VERSION ""

NS_ :

BS_:

BU_: MASTER BRIDGE MOTOR SENSOR GPS

BO_ 103 BRIDGE_NODE: 1 BRIDGE
 SG_ BRIDGE_START : 0|1@1+ (1,0) [0|1] "" MASTER

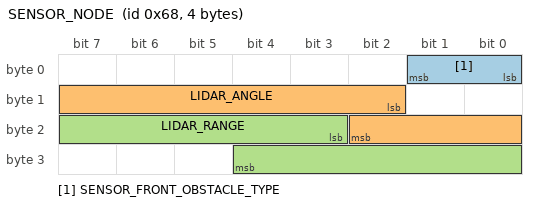
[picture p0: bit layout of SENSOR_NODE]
BO_ 104 SENSOR_NODE: 4 SENSOR
 SG_ SENSOR_FRONT_OBSTACLE_TYPE : 0|2@1+ (1,0) [0|0] "" MASTER
 SG_ LIDAR_ANGLE : 10|9@1+ (1,0) [0|360] "Degrees" MASTER
 SG_ LIDAR_RANGE : 19|10@1+ (1,0) [15|600] "cm" MASTER

BO_ 105 MOTOR_NODE: 1 MASTER
 SG_ MOTOR_DRIVE_CMD : 0|3@1+ (1,0) [0|0] "" MOTOR
 SG_ MOTOR_STEER_CMD : 3|3@1+ (1,0) [0|0] "" MOTOR

BO_ 106 BRIDGE_CHECKPOINTS: 8 BRIDGE
 SG_ CHECKPOINT_LAT : 0|28@1+ (0.000001,-90.000000) [-90|90] "Degrees" MASTER,GPS
 SG_ CHECKPOINT_LONG : 28|29@1+ (0.000001,-180.000000) [-180|180] "Degrees" MASTER,GPS

BO_ 107 GPS_LOCATION: 8 GPS
 SG_ CURRENT_LAT : 0|28@1+ (0.000001,-90.000000) [-90|90] "Degrees" MASTER,BRIDGE,MOTOR
 SG_ CURRENT_LONG : 28|29@1+ (0.000001,-180.000000) [-180|180] "Degrees" MASTER,BRIDGE,MOTOR

BO_ 108 COMPASS: 8 GPS
 SG_ CMP_HEADING : 0|12@1+ (0.1,0) [0|359.9] "Degrees" MASTER,BRIDGE,MOTOR
 SG_ CMP_BEARING : 12|12@1+ (0.1,0) [0|359.9] "Degrees" MASTER,BRIDGE,MOTOR

BO_ 109 SENSOR_HEARTBEAT: 1 SENSOR
 SG_ SENSOR_HBT : 0|1@1+ (1,0) [0|1] "" MASTER

BO_ 110 MOTOR_HEARTBEAT: 1 MOTOR
 SG_ MOTOR_HBT : 0|1@1+ (1,0) [0|1] "" MASTER

BO_ 111 GPS_HEARTBEAT: 1 GPS
 SG_ GPS_HBT : 0|1@1+ (1,0) [0|1] "" MASTER

BO_ 112 BRIDGE_HEARTBEAT: 1 BRIDGE
 SG_ BRIDGE_HBT : 0|1@1+ (1,0) [0|1] "" MASTER

CM_ BU_ MASTER "The driver controller driving the car";
CM_ BU_ MOTOR "The motor controller of the car";
CM_ BU_ SENSOR "The sensor controller of the car";
CM_ BU_ BRIDGE "The bridge controller of the car";
CM_ BU_ GPS "The GPS controller of the car";
CM_ BO_ 100 "Sync message used to synchronize the controllers";

BA_DEF_DEF_ "BusType" "CAN";
BA_DEF_DEF_ "FieldType" "";
BA_DEF_DEF_ "GenMsgCycleTime" 0;

BA_ "GenMsgCycleTime" BO_ 500 100;
BA_ "GenMsgCycleTime" BO_ 100 1000;
BA_ "GenMsgCycleTime" BO_ 101 100;
BA_ "GenMsgCycleTime" BO_ 400 100;
BA_ "GenMsgCycleTime" BO_ 200 100;
BA_ "FieldType" SG_ 104 SENSOR_FRONT_OBSTACLE_TYPE "SENSOR_FRONT_OBSTACLE_TYPE";
BA_ "FieldType" SG_ 105 MOTOR_DRIVE_CMD "MOTOR_DRIVE_CMD";
BA_ "FieldType" SG_ 105 MOTOR_STEER_CMD "MOTOR_STEER_CMD";

VAL_ 104 SENSOR_FRONT_OBSTACLE_TYPE 0 "NO_OBSTACLE" 1 "OBSTACLE_NEAR" 2 "OBSTACLE_FAR";
VAL_ 105 MOTOR_DRIVE_CMD 2 "MOTOR_STOP" 1 "MOTOR_REV" 3 "MOTOR_FWD_SLOW" 4 "MOTOR_FWD_MED" 5 "MOTOR_FWD_FAST" ;
VAL_ 105 MOTOR_STEER_CMD 2 "MOTOR_DONT_STEER" 1 "MOTOR_STEER_SLIGHT_LEFT" 0 "MOTOR_STEER_FULL_LEFT" 3 "MOTOR_STEER_SLIGHT_RIGHT" 4 "MOTOR_STEER_FULL_RIGHT" ;
